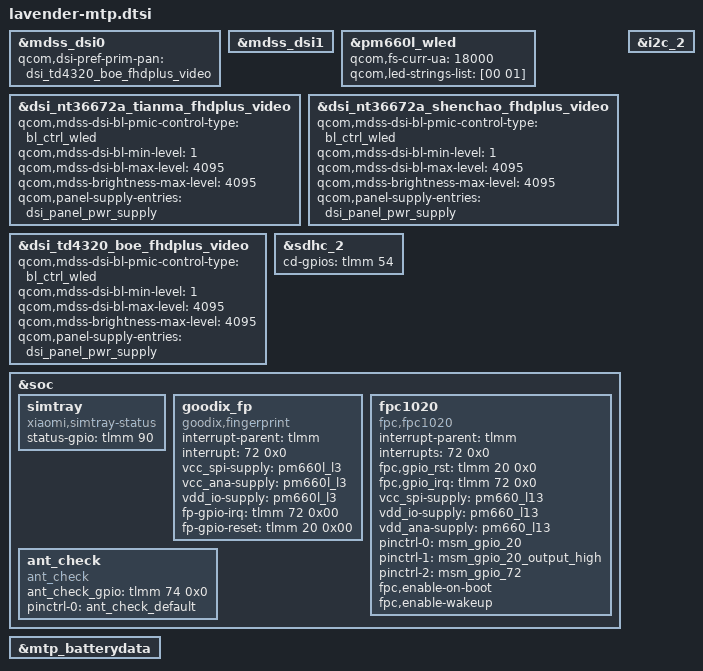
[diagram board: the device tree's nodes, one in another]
/* sdm660-mtp.dtsi diff */
&mdss_dsi0 {
	qcom,dsi-pref-prim-pan = <&dsi_td4320_boe_fhdplus_video>;
};

&mdss_dsi1 {
	/delete-property/ pinctrl-names;
	/delete-property/ pinctrl-0;
	/delete-property/ pinctrl-1;
	/delete-property/ qcom,platform-reset-gpio;
	/delete-property/ qcom,platform-te-gpio;
	/delete-property/ qcom,dsi-pref-prim-pan;
};

&pm660l_wled {
	qcom,fs-curr-ua = <18000>;
	qcom,led-strings-list = [00 01];
};

&dsi_nt36672a_tianma_fhdplus_video {
	qcom,mdss-dsi-bl-pmic-control-type = "bl_ctrl_wled";
	qcom,mdss-dsi-bl-min-level = <1>;
	qcom,mdss-dsi-bl-max-level = <4095>;
	qcom,mdss-brightness-max-level = <4095>;
	qcom,panel-supply-entries = <&dsi_panel_pwr_supply>;
};

&dsi_nt36672a_shenchao_fhdplus_video {
	qcom,mdss-dsi-bl-pmic-control-type = "bl_ctrl_wled";
	qcom,mdss-dsi-bl-min-level = <1>;
	qcom,mdss-dsi-bl-max-level = <4095>;
	qcom,mdss-brightness-max-level = <4095>;
	qcom,panel-supply-entries = <&dsi_panel_pwr_supply>;
};

&dsi_td4320_boe_fhdplus_video {
	qcom,mdss-dsi-bl-pmic-control-type = "bl_ctrl_wled";
	qcom,mdss-dsi-bl-min-level = <1>;
	qcom,mdss-dsi-bl-max-level = <4095>;
	qcom,mdss-brightness-max-level = <4095>;
	qcom,panel-supply-entries = <&dsi_panel_pwr_supply>;
};

&sdhc_2 {
	cd-gpios = <&tlmm 54 0x0>;
};

&soc {
	simtray {
		compatible = "xiaomi,simtray-status";
		status-gpio = <&tlmm 90 0x00>;
	};

	goodix_fp {
		compatible = "goodix,fingerprint";
		interrupt-parent = <&tlmm>;
		interrupt = <72 0x0>;
		vcc_spi-supply = <&pm660l_l3>;
		vcc_ana-supply = <&pm660l_l3>;
		vdd_io-supply = <&pm660l_l3>;
		fp-gpio-irq = <&tlmm 72 0x00>;
		fp-gpio-reset = <&tlmm 20 0x00>;
		status = "okay";
	};

	fpc1020 {
		status = "ok";
		compatible = "fpc,fpc1020";
		interrupt-parent = <&tlmm>;
		interrupts = <72 0x0>;
		fpc,gpio_rst    = <&tlmm 20 0x0>;
		fpc,gpio_irq    = <&tlmm 72 0x0>;
		vcc_spi-supply  = <&pm660_l13>;
		vdd_io-supply   = <&pm660_l13>;
		vdd_ana-supply  = <&pm660_l13>;
		pinctrl-names = "fpc1020_reset_reset",
			"fpc1020_reset_active",
			"fpc1020_irq_active";
		pinctrl-0 = <&msm_gpio_20>;
		pinctrl-1 = <&msm_gpio_20_output_high>;
		pinctrl-2 = <&msm_gpio_72>;
		fpc,enable-on-boot;
		fpc,enable-wakeup;
	};

	ant_check {
		compatible = "ant_check";
		ant_check_gpio = <&tlmm 74 0x0>;
		pinctrl-names = "default";
		pinctrl-0 = <&ant_check_default>;
	};
};

&i2c_2 {
	/delete-property/ status;
	/delete-node/ smb1351-charger@1d;
};

#include "touchscreen/sdm660-novatek-i2c_f7a.dtsi"
#include "touchscreen/sdm660-synaptics-tcm-i2c_f7a.dtsi"

&mtp_batterydata {
	#include "batterydata/fg-gen3-batterydata-m6100atl-4000mah.dtsi"
	#include "batterydata/fg-gen3-batterydata-m6100cos-4000mah.dtsi"
	#include "batterydata/fg-gen3-batterydata-m6100sun-4000mah.dtsi"
	#include "batterydata/fg-gen3-batterydata-m6100default-4000mah.dtsi"
};

